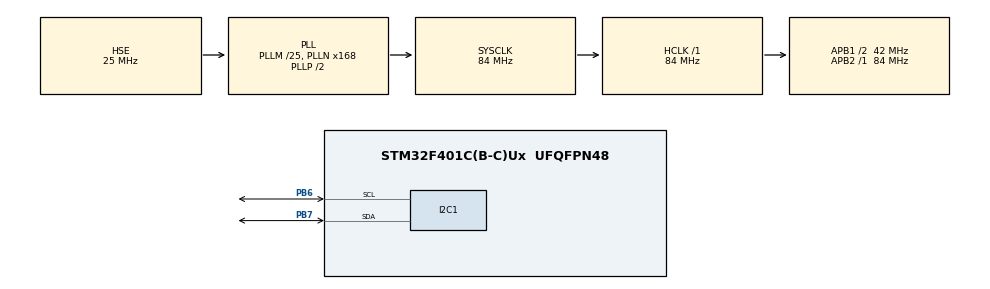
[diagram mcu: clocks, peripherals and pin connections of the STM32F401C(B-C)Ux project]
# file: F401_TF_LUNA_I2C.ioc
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I2C1.I2C_Mode=I2C_Fast
Mcu.Family=STM32F4
Mcu.Name=STM32F401C(B-C)Ux
Mcu.Package=UFQFPN48
NVIC.PriorityGroup=NVIC_PRIORITYGROUP_4
PA13.Mode=Trace_Asynchronous_SW
PA13.Signal=SYS_JTMS-SWDIO
PA14.Mode=Trace_Asynchronous_SW
PA14.Signal=SYS_JTCK-SWCLK
PB3.Mode=Trace_Asynchronous_SW
PB3.Signal=SYS_JTDO-SWO
PB6.Mode=I2C
PB6.Signal=I2C1_SCL
PB7.Mode=I2C
PB7.Signal=I2C1_SDA
PH0\ -\ OSC_IN.Mode=HSE-External-Oscillator
PH0\ -\ OSC_IN.Signal=RCC_OSC_IN
PH1\ -\ OSC_OUT.Mode=HSE-External-Oscillator
PH1\ -\ OSC_OUT.Signal=RCC_OSC_OUT
ProjectManager.HeapSize=0x200
ProjectManager.StackSize=0x400
ProjectManager.TargetToolchain=STM32CubeIDE
RCC.48MHZClocksFreq_Value=42000000
RCC.AHBFreq_Value=84000000
RCC.APB1CLKDivider=RCC_HCLK_DIV2
RCC.APB1Freq_Value=42000000
RCC.APB1TimFreq_Value=84000000
RCC.APB2Freq_Value=84000000
RCC.APB2TimFreq_Value=84000000
RCC.CortexFreq_Value=84000000
RCC.HCLKFreq_Value=84000000
RCC.HSE_VALUE=25000000
RCC.HSI_VALUE=16000000
RCC.LSE_VALUE=32768
RCC.PLLM=25
RCC.PLLN=168
RCC.PLLSourceVirtual=RCC_PLLSOURCE_HSE
RCC.SYSCLKFreq_VALUE=84000000
RCC.SYSCLKSource=RCC_SYSCLKSOURCE_PLLCLK
RCC.VCOOutputFreq_Value=168000000
board=custom

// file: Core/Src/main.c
/* USER CODE BEGIN Header */
/**
  ******************************************************************************
  * @file           : main.c
  * @brief          : Main program body
  ******************************************************************************
  * @attention
  *
  * <h2><center>&copy; Copyright (c) 2021 STMicroelectronics.
  * All rights reserved.</center></h2>
  *
  * This software component is licensed by ST under BSD 3-Clause license,
  * the "License"; You may not use this file except in compliance with the
  * License. You may obtain a copy of the License at:
  *                        opensource.org/licenses/BSD-3-Clause
  *
  ******************************************************************************
  */
/* USER CODE END Header */
#include "main.h"
#include "i2c.h"
#include "gpio.h"

/* USER CODE BEGIN Includes */
#include "tfluna_i2c.h"
#include "stdio.h"
/* USER CODE END Includes */

void SystemClock_Config(void);

/* USER CODE BEGIN 0 */
// Use these defraults or insert your own values

//Printf Debug,SWV Trace
int _write(int file, char *ptr, int len)
{
  /* Implement your write code here, this is used by puts and printf for example */
  int i=0;
  for(i=0 ; i<len ; i++)
    ITM_SendChar((*ptr++));
  return len;
}

TF_Luna_Lidar TF_Luna_1;

/* multi devices example:
 * TF_Luna_Lidar TF_Luna_2;
 * TF_Luna_Lidar TF_Luna_3;
 * TF_Luna_Lidar TF_Luna_4;
 * TF_Luna_Lidar TF_Luna_5;
 */

int16_t  tfAddr = TFL_DEF_ADR;    // default I2C address
uint16_t tfFrame = TFL_DEF_FPS;   // default frame rate

// device variables passed back by getData
int16_t  tfDist = 0 ;   // distance in centimeters

/* multi devices example:
 * Maybe 5 devices
 * int16_t tfDist[5]=0;
 *
 *
 *You should define other variables this way as well.
 *Example : tfFlux[5]=0;
 */

int16_t  tfFlux = 0 ;   // signal quality in arbitrary units
int16_t  tfTemp = 0 ;   // temperature in 0.01 degree Celsius

// other device variables
uint16_t tfTime = 0;    // devie clock in milliseconds

uint8_t  tfVer[3];      // device version number
/*multi devices example:
 * uint8_t  tfVer1[3];
 * uint8_t  tfVer2[3];
 * uint8_t  tfVer3[3];
 * uint8_t  tfVer4[3];
 */

uint8_t  tfCode[14];    // device serial number

// sub-loop counter for Time display
uint8_t tfCount = 0;
/* USER CODE END 0 */

int main(void)
{

  /* MCU Configuration--------------------------------------------------------*/

  /* Reset of all peripherals, Initializes the Flash interface and the Systick. */
  HAL_Init();

  /* Configure the system clock */
  SystemClock_Config();

  /* Initialize all configured peripherals */
  MX_GPIO_Init();
  MX_I2C1_Init();
  /* USER CODE BEGIN 2 */

  TF_Luna_init(&TF_Luna_1, &hi2c1, 0x10);
  /* multi devices example:
   *   If you want to connect more than one device,
   *   you must first connect them one by one and change their slave addresses.
   *   Each device must have a different address.
   *
   *   TF_Luna_init(&TF_Luna_2, &hi2c1, 0x11); // random address.
   *   TF_Luna_init(&TF_Luna_3, &hi2c1, 0x12);
   *   TF_Luna_init(&TF_Luna_4, &hi2c1, 0x13);
   *   TF_Luna_init(&TF_Luna_5, &hi2c1, 0x14);
   */

  Get_Frame_Rate( &TF_Luna_1,&tfFrame);
  Get_Firmware_Version(&TF_Luna_1, tfVer);
  Get_Prod_Code(&TF_Luna_1, tfCode);
  Get_Time(&TF_Luna_1, &tfTime);
  /* USER CODE END 2 */

  /* Infinite loop */
  while (1)
  {

    /* USER CODE BEGIN 3 */
	  getData(&TF_Luna_1, &tfDist, &tfFlux, &tfTemp);

	  /* multi devices example:
	   * 	  getData(&TF_Luna_1, &tfDist[0], &tfFlux[0], &tfTemp[0]);
	   * 	  getData(&TF_Luna_2, &tfDist[1], &tfFlux[1], &tfTemp[1]);
	   * 	  getData(&TF_Luna_3, &tfDist[2], &tfFlux[2], &tfTemp[2]);
	   * 	  getData(&TF_Luna_4, &tfDist[3], &tfFlux[3], &tfTemp[3]);
	   * 	  getData(&TF_Luna_5, &tfDist[4], &tfFlux[4], &tfTemp[4]);
	   *
	   */

	  printf(tfDist); // Open your SVW ITM Data Console

	  /* multi devices example:
	   * printf(tfDist[0]);
	   * printf(tfDist[1]);
	   * printf(tfDist[2]);
	   * printf(tfDist[3]);
	   * printf(tfDist[4]);
	   *
	   */

	  printDataArray();

	  HAL_Delay(4); // 250Hz

  }
  /* USER CODE END 3 */
}

void SystemClock_Config(void)
{
  RCC_OscInitTypeDef RCC_OscInitStruct = {0};
  RCC_ClkInitTypeDef RCC_ClkInitStruct = {0};

  /** Configure the main internal regulator output voltage
  */
  __HAL_RCC_PWR_CLK_ENABLE();
  __HAL_PWR_VOLTAGESCALING_CONFIG(PWR_REGULATOR_VOLTAGE_SCALE2);
  /** Initializes the RCC Oscillators according to the specified parameters
  * in the RCC_OscInitTypeDef structure.
  */
  RCC_OscInitStruct.OscillatorType = RCC_OSCILLATORTYPE_HSE;
  RCC_OscInitStruct.HSEState = RCC_HSE_ON;
  RCC_OscInitStruct.PLL.PLLState = RCC_PLL_ON;
  RCC_OscInitStruct.PLL.PLLSource = RCC_PLLSOURCE_HSE;
  RCC_OscInitStruct.PLL.PLLM = 25;
  RCC_OscInitStruct.PLL.PLLN = 168;
  RCC_OscInitStruct.PLL.PLLP = RCC_PLLP_DIV2;
  RCC_OscInitStruct.PLL.PLLQ = 4;
  if (HAL_RCC_OscConfig(&RCC_OscInitStruct) != HAL_OK)
  {
    Error_Handler();
  }
  /** Initializes the CPU, AHB and APB buses clocks
  */
  RCC_ClkInitStruct.ClockType = RCC_CLOCKTYPE_HCLK|RCC_CLOCKTYPE_SYSCLK
                              |RCC_CLOCKTYPE_PCLK1|RCC_CLOCKTYPE_PCLK2;
  RCC_ClkInitStruct.SYSCLKSource = RCC_SYSCLKSOURCE_PLLCLK;
  RCC_ClkInitStruct.AHBCLKDivider = RCC_SYSCLK_DIV1;
  RCC_ClkInitStruct.APB1CLKDivider = RCC_HCLK_DIV2;
  RCC_ClkInitStruct.APB2CLKDivider = RCC_HCLK_DIV1;

  if (HAL_RCC_ClockConfig(&RCC_ClkInitStruct, FLASH_LATENCY_2) != HAL_OK)
  {
    Error_Handler();
  }
}

void Error_Handler(void)
{
  __disable_irq();
  while (1)
  {
  }
}

/************************ (C) COPYRIGHT STMicroelectronics *****END OF FILE****/
